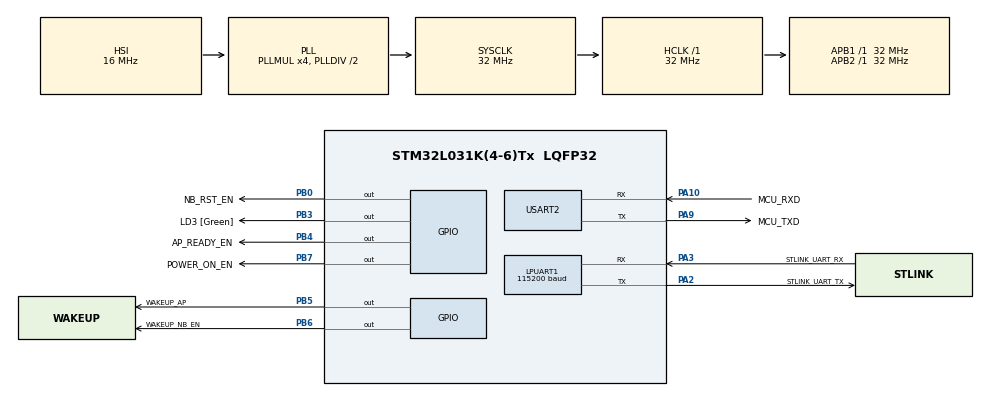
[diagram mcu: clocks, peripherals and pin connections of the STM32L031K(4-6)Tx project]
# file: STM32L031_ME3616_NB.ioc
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Dma.LPUART1_TX.1.Direction=DMA_MEMORY_TO_PERIPH
Dma.LPUART1_TX.1.Instance=DMA1_Channel2
Dma.LPUART1_TX.1.MemDataAlignment=DMA_MDATAALIGN_BYTE
Dma.LPUART1_TX.1.MemInc=DMA_MINC_ENABLE
Dma.LPUART1_TX.1.Mode=DMA_NORMAL
Dma.LPUART1_TX.1.PeriphDataAlignment=DMA_PDATAALIGN_BYTE
Dma.LPUART1_TX.1.PeriphInc=DMA_PINC_DISABLE
Dma.LPUART1_TX.1.Priority=DMA_PRIORITY_HIGH
Dma.Request0=USART2_RX
Dma.Request1=LPUART1_TX
Dma.Request2=USART2_TX
Dma.USART2_RX.0.Direction=DMA_PERIPH_TO_MEMORY
Dma.USART2_RX.0.Instance=DMA1_Channel5
Dma.USART2_RX.0.MemDataAlignment=DMA_MDATAALIGN_BYTE
Dma.USART2_RX.0.MemInc=DMA_MINC_ENABLE
Dma.USART2_RX.0.Mode=DMA_CIRCULAR
Dma.USART2_RX.0.PeriphDataAlignment=DMA_PDATAALIGN_BYTE
Dma.USART2_RX.0.PeriphInc=DMA_PINC_DISABLE
Dma.USART2_RX.0.Priority=DMA_PRIORITY_LOW
Dma.USART2_TX.2.Direction=DMA_MEMORY_TO_PERIPH
Dma.USART2_TX.2.Instance=DMA1_Channel4
Dma.USART2_TX.2.MemDataAlignment=DMA_MDATAALIGN_BYTE
Dma.USART2_TX.2.MemInc=DMA_MINC_ENABLE
Dma.USART2_TX.2.Mode=DMA_NORMAL
Dma.USART2_TX.2.PeriphDataAlignment=DMA_PDATAALIGN_BYTE
Dma.USART2_TX.2.PeriphInc=DMA_PINC_DISABLE
Dma.USART2_TX.2.Priority=DMA_PRIORITY_MEDIUM
LPUART1.BaudRate=115200
LPUART1.Mode=UART_MODE_TX
LPUART1.OneBitSampling=UART_ONE_BIT_SAMPLE_DISABLE
LPUART1.WordLength=UART_WORDLENGTH_8B
Mcu.Family=STM32L0
Mcu.Name=STM32L031K(4-6)Tx
Mcu.Package=LQFP32
NVIC.AES_RNG_LPUART1_IRQn=true\:1\:0\:true\:false\:true\:true
NVIC.DMA1_Channel2_3_IRQn=true\:0\:0\:false\:false\:true\:false
NVIC.DMA1_Channel4_5_6_7_IRQn=true\:0\:0\:false\:false\:true\:false
NVIC.USART2_IRQn=true\:2\:0\:true\:false\:true\:true
PA10.GPIO_Label=MCU_RXD
PA10.GPIO_Speed=GPIO_SPEED_FREQ_MEDIUM
PA10.Mode=Asynchronous
PA10.Signal=USART2_RX
PA13.GPIO_Label=TMS
PA13.Mode=Serial_Wire
PA13.Signal=SYS_SWDIO
PA14.GPIO_Label=TCK
PA14.Mode=Serial_Wire
PA14.Signal=SYS_SWCLK
PA2.GPIO_Label=STLINK_UART_TX
PA2.GPIO_Speed=GPIO_SPEED_FREQ_MEDIUM
PA2.Mode=Asynchronous
PA2.Signal=LPUART1_TX
PA3.GPIO_Label=STLINK_UART_RX
PA3.GPIO_Speed=GPIO_SPEED_FREQ_MEDIUM
PA3.Mode=Asynchronous
PA3.Signal=LPUART1_RX
PA9.GPIO_Label=MCU_TXD
PA9.GPIO_ModeDefaultPP=GPIO_MODE_AF_PP
PA9.GPIO_PuPd=GPIO_NOPULL
PA9.GPIO_Speed=GPIO_SPEED_FREQ_MEDIUM
PA9.Mode=Asynchronous
PA9.Signal=USART2_TX
PB0.GPIO_Label=NB_RST_EN
PB0.Signal=GPIO_Output
PB3.GPIO_Label=LD3 [Green]
PB3.Signal=GPIO_Output
PB4.GPIO_Label=AP_READY_EN
PB4.Signal=GPIO_Output
PB5.GPIO_Label=WAKEUP_AP
PB5.Signal=GPIO_Output
PB6.GPIO_Label=WAKEUP_NB_EN
PB6.Signal=GPIO_Output
PB7.GPIO_Label=POWER_ON_EN
PB7.Signal=GPIO_Output
PC14-OSC32_IN.Mode=LSE-External-Oscillator
PC14-OSC32_IN.Signal=RCC_OSC32_IN
PC15-OSC32_OUT.Mode=LSE-External-Oscillator
PC15-OSC32_OUT.Signal=RCC_OSC32_OUT
ProjectManager.HeapSize=0x400
ProjectManager.StackSize=0x600
ProjectManager.TargetToolchain=EWARM V8
RCC.AHBFreq_Value=32000000
RCC.APB1Freq_Value=32000000
RCC.APB1TimFreq_Value=32000000
RCC.APB2Freq_Value=32000000
RCC.APB2TimFreq_Value=32000000
RCC.HCLKFreq_Value=32000000
RCC.HSE_VALUE=8000000
RCC.HSI16_VALUE=16000000
RCC.HSI48_VALUE=48000000
RCC.HSI_VALUE=16000000
RCC.MSI_VALUE=2097000
RCC.PLLMUL=RCC_PLLMUL_4
RCC.PREFETCH_ENABLE=1
RCC.RTCClockSelection=RCC_RTCCLKSOURCE_LSE
RCC.RTCClockSelectionVirtual=RCC_RTCCLKSOURCE_LSE
RCC.SYSCLKFreq_VALUE=32000000
RCC.SYSCLKSource=RCC_SYSCLKSOURCE_PLLCLK
RCC.VCOOutputFreq_Value=64000000
USART2.VirtualMode-Asynchronous=VM_ASYNC
board=NUCLEO-L031K6

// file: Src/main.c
/**
  ******************************************************************************
  * @file           : main.c
  * @brief          : Main program body
  ******************************************************************************
  ** This notice applies to any and all portions of this file
  * that are not between comment pairs USER CODE BEGIN and
  * USER CODE END. Other portions of this file, whether
  * inserted by the user or by software development tools
  * are owned by their respective copyright owners.
  *
  * COPYRIGHT(c) 2018 STMicroelectronics
  *
  * Redistribution and use in source and binary forms, with or without modification,
  * are permitted provided that the following conditions are met:
  *   1. Redistributions of source code must retain the above copyright notice,
  *      this list of conditions and the following disclaimer.
  *   2. Redistributions in binary form must reproduce the above copyright notice,
  *      this list of conditions and the following disclaimer in the documentation
  *      and/or other materials provided with the distribution.
  *   3. Neither the name of STMicroelectronics nor the names of its contributors
  *      may be used to endorse or promote products derived from this software
  *      without specific prior written permission.
  *
  * THIS SOFTWARE IS PROVIDED BY THE COPYRIGHT HOLDERS AND CONTRIBUTORS "AS IS"
  * AND ANY EXPRESS OR IMPLIED WARRANTIES, INCLUDING, BUT NOT LIMITED TO, THE
  * IMPLIED WARRANTIES OF MERCHANTABILITY AND FITNESS FOR A PARTICULAR PURPOSE ARE
  * DISCLAIMED. IN NO EVENT SHALL THE COPYRIGHT HOLDER OR CONTRIBUTORS BE LIABLE
  * FOR ANY DIRECT, INDIRECT, INCIDENTAL, SPECIAL, EXEMPLARY, OR CONSEQUENTIAL
  * DAMAGES (INCLUDING, BUT NOT LIMITED TO, PROCUREMENT OF SUBSTITUTE GOODS OR
  * SERVICES; LOSS OF USE, DATA, OR PROFITS; OR BUSINESS INTERRUPTION) HOWEVER
  * CAUSED AND ON ANY THEORY OF LIABILITY, WHETHER IN CONTRACT, STRICT LIABILITY,
  * OR TORT (INCLUDING NEGLIGENCE OR OTHERWISE) ARISING IN ANY WAY OUT OF THE USE
  * OF THIS SOFTWARE, EVEN IF ADVISED OF THE POSSIBILITY OF SUCH DAMAGE.
  *
  ******************************************************************************
  */
#include "main.h"
#include "stm32l0xx_hal.h"
#include "dma.h"
#include "usart.h"
#include "gpio.h"

/* USER CODE BEGIN Includes */

#include "me3616.h"

/* USER CODE END Includes */

/* USER CODE BEGIN PV */
/* Private variables ---------------------------------------------------------*/
extern UART_HandleTypeDef hlpuart1;
extern UART_HandleTypeDef huart2;
extern DMA_HandleTypeDef hdma_usart2_tx;
extern DMA_HandleTypeDef hdma_usart2_rx;

/* USER CODE END PV */

void SystemClock_Config(void);

/* USER CODE BEGIN PFP */
/* Private function prototypes -----------------------------------------------*/

/* USER CODE END PFP */

int main(void)
{

  /* MCU Configuration----------------------------------------------------------*/

  /* Reset of all peripherals, Initializes the Flash interface and the Systick. */
  HAL_Init();

  /* Configure the system clock */
  SystemClock_Config();

  /* Initialize all configured peripherals */
  MX_GPIO_Init();
  MX_DMA_Init();
  MX_LPUART1_UART_Init();
  MX_USART2_UART_Init();
  /* USER CODE BEGIN 2 */

  DBG_Print("Start of App ME3616A", DBG_DIR_APP);

  if( ME3616_Init(&ME3616_Instance, &ME3616_UART, &hdma_usart2_tx, &hdma_usart2_rx) == false)
      ME3616_APP_ErrorHandler(__FILE__, __LINE__, "ME3616 Boot Timeout.");
  ME3616_APP(&ME3616_Instance);

  DBG_Print("End of App ME3616A",DBG_DIR_APP);

  /* USER CODE END 2 */

  /* Infinite loop */
  /* USER CODE BEGIN WHILE */
  while (1)
  {
  	  HAL_Delay(20000);
      DBG_Print("Demo End.",DBG_DIR_APP);

  /* USER CODE END WHILE */

  }

}

void SystemClock_Config(void)
{

  RCC_OscInitTypeDef RCC_OscInitStruct;
  RCC_ClkInitTypeDef RCC_ClkInitStruct;
  RCC_PeriphCLKInitTypeDef PeriphClkInit;

    /**Configure the main internal regulator output voltage
    */
  __HAL_PWR_VOLTAGESCALING_CONFIG(PWR_REGULATOR_VOLTAGE_SCALE1);

    /**Initializes the CPU, AHB and APB busses clocks
    */
  RCC_OscInitStruct.OscillatorType = RCC_OSCILLATORTYPE_HSI;
  RCC_OscInitStruct.HSIState = RCC_HSI_ON;
  RCC_OscInitStruct.HSICalibrationValue = 16;
  RCC_OscInitStruct.PLL.PLLState = RCC_PLL_ON;
  RCC_OscInitStruct.PLL.PLLSource = RCC_PLLSOURCE_HSI;
  RCC_OscInitStruct.PLL.PLLMUL = RCC_PLLMUL_4;
  RCC_OscInitStruct.PLL.PLLDIV = RCC_PLLDIV_2;
  if (HAL_RCC_OscConfig(&RCC_OscInitStruct) != HAL_OK)
  {
    _Error_Handler(__FILE__, __LINE__);
  }

    /**Initializes the CPU, AHB and APB busses clocks
    */
  RCC_ClkInitStruct.ClockType = RCC_CLOCKTYPE_HCLK|RCC_CLOCKTYPE_SYSCLK
                              |RCC_CLOCKTYPE_PCLK1|RCC_CLOCKTYPE_PCLK2;
  RCC_ClkInitStruct.SYSCLKSource = RCC_SYSCLKSOURCE_PLLCLK;
  RCC_ClkInitStruct.AHBCLKDivider = RCC_SYSCLK_DIV1;
  RCC_ClkInitStruct.APB1CLKDivider = RCC_HCLK_DIV1;
  RCC_ClkInitStruct.APB2CLKDivider = RCC_HCLK_DIV1;

  if (HAL_RCC_ClockConfig(&RCC_ClkInitStruct, FLASH_LATENCY_1) != HAL_OK)
  {
    _Error_Handler(__FILE__, __LINE__);
  }

  PeriphClkInit.PeriphClockSelection = RCC_PERIPHCLK_USART2|RCC_PERIPHCLK_LPUART1;
  PeriphClkInit.Usart2ClockSelection = RCC_USART2CLKSOURCE_PCLK1;
  PeriphClkInit.Lpuart1ClockSelection = RCC_LPUART1CLKSOURCE_PCLK1;
  if (HAL_RCCEx_PeriphCLKConfig(&PeriphClkInit) != HAL_OK)
  {
    _Error_Handler(__FILE__, __LINE__);
  }

    /**Configure the Systick interrupt time
    */
  HAL_SYSTICK_Config(HAL_RCC_GetHCLKFreq()/1000);

    /**Configure the Systick
    */
  HAL_SYSTICK_CLKSourceConfig(SYSTICK_CLKSOURCE_HCLK);

  /* SysTick_IRQn interrupt configuration */
  HAL_NVIC_SetPriority(SysTick_IRQn, 0, 0);
}

void _Error_Handler(char *file, int line)
{
  while(1)
  {
  }
}

/************************ (C) COPYRIGHT STMicroelectronics *****END OF FILE****/
